# KM1M7CF13 register map
Vendor: Nuvoton Technology Corporation Japan; Series: KM1M7CF; File version: 1.0.3
CPU: CM7 r1p2, little endian, MPU, FPU, double-precision FPU, I-cache, D-cache, ITCM, DTCM, 4 interrupt priority bits
Registers are 32-bit, read-write, no defined reset value unless marked. A register's access mark holds for its fields unless they carry their own. Offsets are from the block's base; [hi:lo] are bit positions; {n}, {i} and the like mark numbered series; 'fields as' and 'values as' point back to an identical list.

## WDT — Watchdog Timer
Base 0x40004000
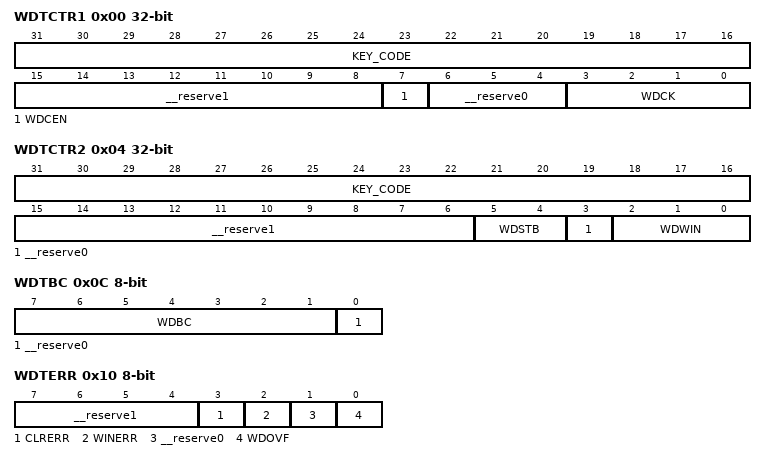
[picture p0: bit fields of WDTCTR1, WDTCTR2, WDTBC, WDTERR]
0x00 WDTCTR1 access per field — Watchdog Timer Control Register 1
  [31:16] KEY_CODE wo — Register Key
  [15:8] __reserve1 ro — "0" is always read out.
  [7] WDCEN rw — WDT count enable
  [6:4] __reserve0 ro — "0" is always read out.
  [3:0] WDCK rw — Selection of binary counter clock source
0x04 WDTCTR2 access per field — Watchdog Timer Control Register 2
  [31:16] KEY_CODE wo — Register Key
  [15:6] __reserve1 ro — "0" is always read out.
  [5:4] WDSTB rw — WDT count control in standby mode (SLEEP mode, DEEPSLEEP mode)
  [3] __reserve0 ro — "0" is always read out.
  [2:0] WDWIN rw — Settings of the time WDT counter can be cleared (window open period)
0x08 WDTCLR 8-bit wo — Watchdog Timer Clear Register
  [7:0] WDCL — Writing "0xA5" clears WDT counter.
0x0C WDTBC 8-bit ro — Watchdog Timer Binary Counter
  [7:1] WDBC — Value of WDT binary counter is read out.
  [0] __reserve0 — "0" is always read out.
0x10 WDTERR 8-bit ro — Watchdog Timer Error Flag Register
  [7:4] __reserve1 — "0" is always read out.
  [3] CLRERR — Occurrence of WDT clear data error
  [2] WINERR — Occurrence of WDT window error
  [1] __reserve0 — "0" is always read out.
  [0] WDOVF — Occurrence of WDT overflow error
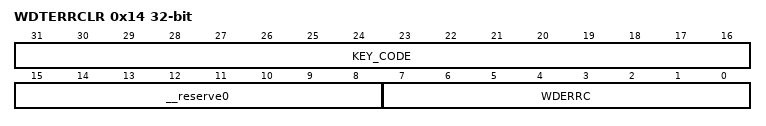
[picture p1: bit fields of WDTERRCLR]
0x14 WDTERRCLR access per field — Watchdog Timer Error Flag Clear Register
  [31:16] KEY_CODE wo — Register Key
  [15:8] __reserve0 ro — "0" is always read out.
  [7:0] WDERRC wo — The corresponding bit of WDTERR is cleared by writing "1" to each bit.

## CRC — CRC Calculation Circuit
Base 0x40009000
0x00 CRC0DATA_MSB wo — CRC0 Data Register MSB 1st
  [31:0] DATA_MSB — Set the data for CRC calculation in 32-bit units. The calculation is handled as Most Significant Bit (MSB) First.
0x04 CRC0DATA_LSB wo — CRC0 Data Register LSB 1st
  [31:0] DATA_LSB — Set the data for CRC calculation in 32-bit units. The calculation is handled as Least Significant Bit (LSB) First.
0x08 CRC0RES_MSB — CRC0 Checksum Register MSB 1st
  [31:0] RES_MSB — A read access to this register reads out the CRC0 checksum value with MSB First.
0x0C CRC0RES_LSB ro — CRC0 Checksum Register LSB 1st
  [31:0] RES_LSB — A read access to this register reads out CRC0 checksum value with LSB First.
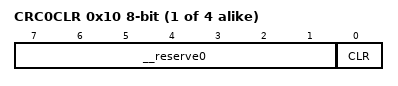
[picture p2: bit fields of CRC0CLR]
{0x10+0x20*i} CRC{i}CLR 8-bit access per field (i=0..3) — CRC{i} Clear Register
  [7:1] __reserve0 ro — "0" is always read out.
  [0] CLR wo — Set CRC{i} seed value.
0x20 CRC1DATA_MSB 8-bit wo — CRC1 Data Register MSB 1st
  [7:0] DATA_MSB — Set the data for CRC calculation in 8-bit units. The calculation is handled as Most Significant Bit (MSB) First.
{0x4+0x20*i} CRC{i}DATA_LSB 8-bit wo (i=1..3) — CRC{i} Data Register LSB 1st
  [7:0] DATA_LSB — Set the data for CRC calculation in 8-bit units. The calculation is handled as Least Significant Bit (LSB) First.
0x28 CRC1RES_MSB 16-bit — CRC1 Checksum Register MSB 1st
  [15:0] RES_MSB — A read access to this register reads out the CRC1 checksum value with MSB First.
0x2C CRC1RES_LSB 16-bit ro — CRC1 Checksum Register LSB 1st
  [15:0] RES_LSB — A read access to this register reads out CRC1 checksum value with LSB First.
0x40 CRC2DATA_MSB 8-bit wo — CRC2 Data Register MSB 1st
  fields as CRC1DATA_MSB
0x48 CRC2RES_MSB 16-bit — CRC2 Checksum Register MSB 1st
  [15:0] RES_MSB — A read access to this register reads out the CRC2 checksum value with MSB First.
0x4C CRC2RES_LSB 16-bit ro — CRC2 Checksum Register LSB 1st
  [15:0] RES_LSB — A read access to this register reads out CRC2 checksum value with LSB First.
0x60 CRC3DATA_MSB 8-bit wo — CRC3Data Register MSB 1st
  fields as CRC1DATA_MSB
0x68 CRC3RES_MSB 8-bit — CRC3 Checksum Register MSB 1st
  [7:0] RES_MSB — A read access to this register reads out the CRC3 checksum value with MSB First.
0x6C CRC3RES_LSB 8-bit ro — CRC3 Checksum Register LSB 1st
  [7:0] RES_LSB — A read access to this register reads out CRC3 checksum value with LSB First.
